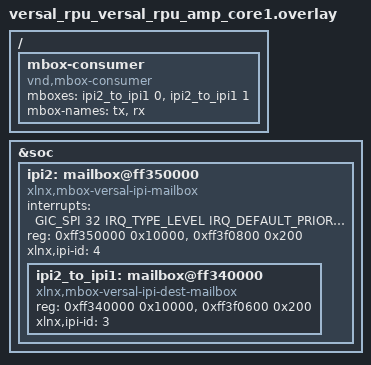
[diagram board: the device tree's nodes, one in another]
/*
 * Copyright (c) 2026 Advanced Micro Devices, Inc.
 *
 * SPDX-License-Identifier: Apache-2.0
 *
 * Versal RPU AMP Core 1 — IPI mailbox overlay
 *
 * Local agent:  IPI2 (id=4, ctrl=0xff350000, SPI 32)
 * Remote agent: IPI1 (id=3, ctrl=0xff340000)
 *
 * Versal RPU DTSI does not include IPI nodes, so we define
 * the full parent + child here.
 *
 * Core 1 sends via IPI2→IPI1 (triggers IPI1 interrupt on Core 0).
 * Core 1 receives via IPI2 when Core 0 triggers IPI2 from IPI1.
 */

#include <zephyr/dt-bindings/interrupt-controller/arm-gic.h>

&soc {
	ipi2: mailbox@ff350000 {
		compatible = "xlnx,mbox-versal-ipi-mailbox";
		status = "okay";
		interrupts = <GIC_SPI 32 IRQ_TYPE_LEVEL IRQ_DEFAULT_PRIORITY>;
		reg = <0xff350000 0x10000>, <0xff3f0800 0x200>;
		reg-names = "ctrl", "msg";
		xlnx,ipi-id = <4>;
		#address-cells = <1>;
		#size-cells = <1>;

		ipi2_to_ipi1: mailbox@ff340000 {
			compatible = "xlnx,mbox-versal-ipi-dest-mailbox";
			reg = <0xff340000 0x10000>, <0xff3f0600 0x200>;
			reg-names = "ctrl", "msg";
			xlnx,ipi-id = <3>;
			#mbox-cells = <1>;
		};
	};
};

/ {
	mbox-consumer {
		compatible = "vnd,mbox-consumer";
		mboxes = <&ipi2_to_ipi1 0>, <&ipi2_to_ipi1 1>;
		mbox-names = "tx", "rx";
	};
};
